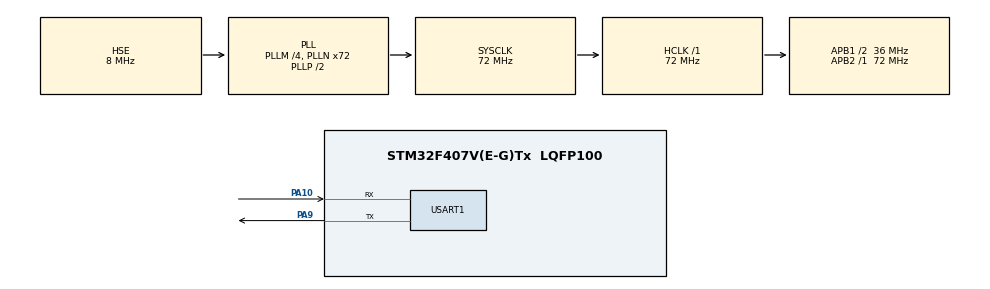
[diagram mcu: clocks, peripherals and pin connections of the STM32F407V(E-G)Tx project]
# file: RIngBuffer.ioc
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Mcu.Family=STM32F4
RCC.PLLSourceVirtual=RCC_PLLSOURCE_HSE
PH0-OSC_IN.Signal=RCC_OSC_IN
RCC.CortexFreq_Value=72000000
PA10.Mode=Asynchronous
RCC.APB1CLKDivider=RCC_HCLK_DIV2
RCC.SYSCLKSource=RCC_SYSCLKSOURCE_PLLCLK
ProjectManager.StackSize=0x400
PA13.Signal=SYS_JTMS-SWDIO
PA9.Mode=Asynchronous
ProjectManager.TargetToolchain=STM32CubeIDE
RCC.HCLKFreq_Value=72000000
RCC.APB2TimFreq_Value=72000000
PA9.Signal=USART1_TX
RCC.LSE_VALUE=32768
RCC.AHBFreq_Value=72000000
PH0-OSC_IN.Mode=HSE-External-Oscillator
RCC.HSE_VALUE=8000000
board=custom
RCC.VCOOutputFreq_Value=144000000
RCC.APB2Freq_Value=72000000
PA14.Mode=Serial_Wire
PH1-OSC_OUT.Signal=RCC_OSC_OUT
PA13.Mode=Serial_Wire
Mcu.Name=STM32F407V(E-G)Tx
PH1-OSC_OUT.Mode=HSE-External-Oscillator
RCC.48MHZClocksFreq_Value=36000000
RCC.SYSCLKFreq_VALUE=72000000
Mcu.Package=LQFP100
USART1.VirtualMode=VM_ASYNC
PA10.Signal=USART1_RX
PA14.Signal=SYS_JTCK-SWCLK
ProjectManager.HeapSize=0x200
RCC.HSI_VALUE=16000000
NVIC.PriorityGroup=NVIC_PRIORITYGROUP_4
RCC.PLLM=4
RCC.PLLN=72
RCC.APB1TimFreq_Value=72000000
NVIC.USART1_IRQn=true\:0\:0\:false\:false\:true\:true\:true
RCC.APB1Freq_Value=36000000

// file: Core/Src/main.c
/* USER CODE BEGIN Header */
/**
  ******************************************************************************
  * @file           : main.c
  * @brief          : Main program body
  ******************************************************************************
  * @attention
  *
  * <h2><center>&copy; Copyright (c) 2019 STMicroelectronics.
  * All rights reserved.</center></h2>
  *
  * This software component is licensed by ST under BSD 3-Clause license,
  * the "License"; You may not use this file except in compliance with the
  * License. You may obtain a copy of the License at:
  *                        opensource.org/licenses/BSD-3-Clause
  *
  ******************************************************************************
  */
/* USER CODE END Header */
#include "main.h"

/* USER CODE BEGIN Includes */
#include "UartRingbuffer.h"
/* USER CODE END Includes */

UART_HandleTypeDef huart1;

void SystemClock_Config(void);
static void MX_GPIO_Init(void);
static void MX_USART1_UART_Init(void);

/* USER CODE BEGIN 0 */

char buffer[5];

/* USER CODE END 0 */

int main(void)
{

  /* MCU Configuration--------------------------------------------------------*/

  /* Reset of all peripherals, Initializes the Flash interface and the Systick. */
  HAL_Init();

  /* Configure the system clock */
  SystemClock_Config();

  /* Initialize all configured peripherals */
  MX_GPIO_Init();
  MX_USART1_UART_Init();
  /* USER CODE BEGIN 2 */

  Ringbuf_init ();

  /* USER CODE END 2 */

  /* Infinite loop */
  while (1)
  {

    /* USER CODE BEGIN 3 */
	  /* wait_for is replaced by get_pos */

	  int data = Uart_read();
	  Uart_write(data);
/*
	  if (Wait_for("hello"))
	  {
		  Get_after("hello", 2, buffer);
		  Uart_sendstring("received\n");
      }
	  else Uart_sendstring("not received\n");*/

	  HAL_Delay (1000);

  }
  /* USER CODE END 3 */
}

void SystemClock_Config(void)
{
  RCC_OscInitTypeDef RCC_OscInitStruct = {0};
  RCC_ClkInitTypeDef RCC_ClkInitStruct = {0};

  /** Configure the main internal regulator output voltage
  */
  __HAL_RCC_PWR_CLK_ENABLE();
  __HAL_PWR_VOLTAGESCALING_CONFIG(PWR_REGULATOR_VOLTAGE_SCALE1);
  /** Initializes the RCC Oscillators according to the specified parameters
  * in the RCC_OscInitTypeDef structure.
  */
  RCC_OscInitStruct.OscillatorType = RCC_OSCILLATORTYPE_HSE;
  RCC_OscInitStruct.HSEState = RCC_HSE_ON;
  RCC_OscInitStruct.PLL.PLLState = RCC_PLL_ON;
  RCC_OscInitStruct.PLL.PLLSource = RCC_PLLSOURCE_HSE;
  RCC_OscInitStruct.PLL.PLLM = 4;
  RCC_OscInitStruct.PLL.PLLN = 72;
  RCC_OscInitStruct.PLL.PLLP = RCC_PLLP_DIV2;
  RCC_OscInitStruct.PLL.PLLQ = 4;
  if (HAL_RCC_OscConfig(&RCC_OscInitStruct) != HAL_OK)
  {
    Error_Handler();
  }
  /** Initializes the CPU, AHB and APB buses clocks
  */
  RCC_ClkInitStruct.ClockType = RCC_CLOCKTYPE_HCLK|RCC_CLOCKTYPE_SYSCLK
                              |RCC_CLOCKTYPE_PCLK1|RCC_CLOCKTYPE_PCLK2;
  RCC_ClkInitStruct.SYSCLKSource = RCC_SYSCLKSOURCE_PLLCLK;
  RCC_ClkInitStruct.AHBCLKDivider = RCC_SYSCLK_DIV1;
  RCC_ClkInitStruct.APB1CLKDivider = RCC_HCLK_DIV2;
  RCC_ClkInitStruct.APB2CLKDivider = RCC_HCLK_DIV1;

  if (HAL_RCC_ClockConfig(&RCC_ClkInitStruct, FLASH_LATENCY_2) != HAL_OK)
  {
    Error_Handler();
  }
}

static void MX_USART1_UART_Init(void)
{

  huart1.Instance = USART1;
  huart1.Init.BaudRate = 115200;
  huart1.Init.WordLength = UART_WORDLENGTH_8B;
  huart1.Init.StopBits = UART_STOPBITS_1;
  huart1.Init.Parity = UART_PARITY_NONE;
  huart1.Init.Mode = UART_MODE_TX_RX;
  huart1.Init.HwFlowCtl = UART_HWCONTROL_NONE;
  huart1.Init.OverSampling = UART_OVERSAMPLING_16;
  if (HAL_UART_Init(&huart1) != HAL_OK)
  {
    Error_Handler();
  }

}

static void MX_GPIO_Init(void)
{

  /* GPIO Ports Clock Enable */
  __HAL_RCC_GPIOH_CLK_ENABLE();
  __HAL_RCC_GPIOA_CLK_ENABLE();

}

void Error_Handler(void)
{
}

/************************ (C) COPYRIGHT STMicroelectronics *****END OF FILE****/
